# STM32F410C8T3 register map
File version: 1.0
Registers are 32-bit, access not given, reset 0x0 unless marked. A register's access mark holds for its fields unless they carry their own. Offsets are from the block's base; [hi:lo] are bit positions; {n}, {i} and the like mark numbered series.

## WWDG
Base 0x40002C00
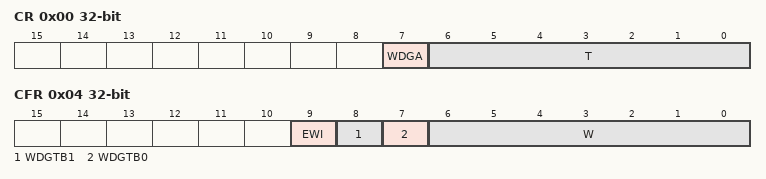
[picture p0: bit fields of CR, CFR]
0x00 CR
  [7] WDGA, [6:0] T
0x04 CFR
  [9] EWI, [8] WDGTB1, [7] WDGTB0, [6:0] W
0x08 SR
  [0] EWIF

## IWDG
Base 0x40003000
0x00 KR
  [15:0] KEY
0x04 PR
  [2:0] PR
0x08 RLR
  [11:0] RL
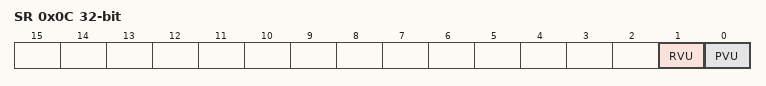
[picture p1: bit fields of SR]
0x0C SR
  [1] RVU, [0] PVU

## SPI2
Base 0x40003800
Same registers: SPI1 0x40013000, SPI5 0x40015000
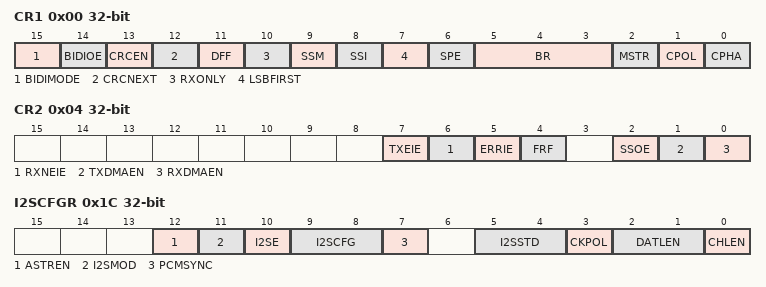
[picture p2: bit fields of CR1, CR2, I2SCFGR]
0x00 CR1
  [15] BIDIMODE, [14] BIDIOE, [13] CRCEN, [12] CRCNEXT, [11] DFF, [10] RXONLY, [9] SSM, [8] SSI, [7] LSBFIRST, [6] SPE, [5:3] BR, [2] MSTR, [1] CPOL, [0] CPHA
0x04 CR2
  [7] TXEIE, [6] RXNEIE, [5] ERRIE, [4] FRF, [2] SSOE, [1] TXDMAEN, [0] RXDMAEN
0x08 SR
0x0C DR
  [15:0] DR
0x10 CRCPR
  [15:0] CRCPOLY
0x14 RXCRCR
  [15:0] RxCRC
0x18 TXCRCR
  [15:0] TxCRC
0x1C I2SCFGR
  [12] ASTREN, [11] I2SMOD, [10] I2SE, [9:8] I2SCFG, [7] PCMSYNC, [5:4] I2SSTD, [3] CKPOL, [2:1] DATLEN, [0] CHLEN
0x20 I2SPR

## USART2
Base 0x40004400
Same registers: USART1 0x40011000, USART6 0x40011400
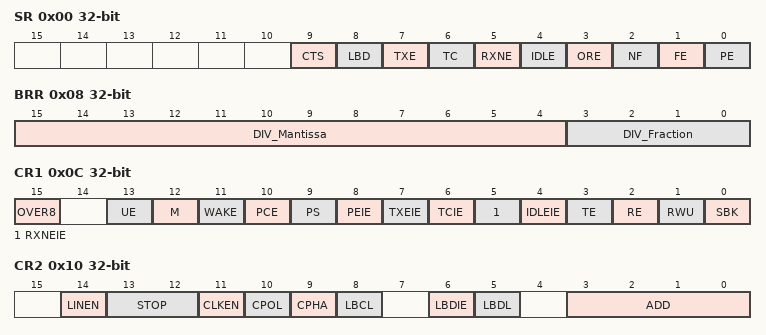
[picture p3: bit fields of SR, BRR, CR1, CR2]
0x00 SR
  [9] CTS, [8] LBD, [7] TXE, [6] TC, [5] RXNE, [4] IDLE, [3] ORE, [2] NF, [1] FE, [0] PE
0x04 DR
  [8:0] DR
0x08 BRR
  [15:4] DIV_Mantissa, [3:0] DIV_Fraction
0x0C CR1
  [15] OVER8, [13] UE, [12] M, [11] WAKE, [10] PCE, [9] PS, [8] PEIE, [7] TXEIE, [6] TCIE, [5] RXNEIE, [4] IDLEIE, [3] TE, [2] RE, [1] RWU, [0] SBK
0x10 CR2
  [14] LINEN, [13:12] STOP, [11] CLKEN, [10] CPOL, [9] CPHA, [8] LBCL, [6] LBDIE, [5] LBDL, [3:0] ADD
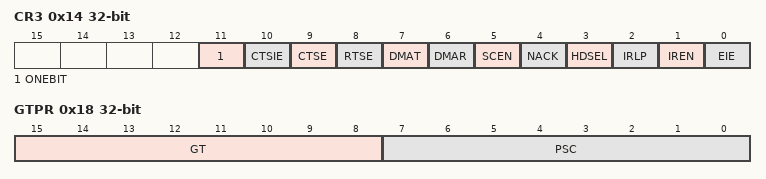
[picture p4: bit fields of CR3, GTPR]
0x14 CR3
  [11] ONEBIT, [10] CTSIE, [9] CTSE, [8] RTSE, [7] DMAT, [6] DMAR, [5] SCEN, [4] NACK, [3] HDSEL, [2] IRLP, [1] IREN, [0] EIE
0x18 GTPR
  [15:8] GT, [7:0] PSC

## I2C1
Base 0x40005400
Same registers: I2C2 0x40005800, I2C4FM 0x40006000
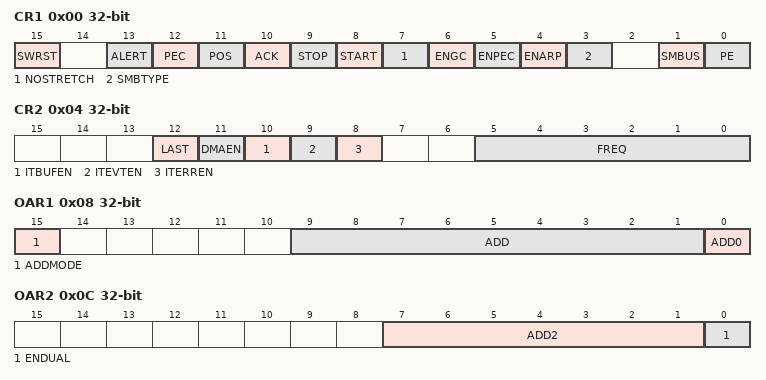
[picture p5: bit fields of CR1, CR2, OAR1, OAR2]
0x00 CR1
  [15] SWRST, [13] ALERT, [12] PEC, [11] POS, [10] ACK, [9] STOP, [8] START, [7] NOSTRETCH, [6] ENGC, [5] ENPEC, [4] ENARP, [3] SMBTYPE, [1] SMBUS, [0] PE
0x04 CR2
  [12] LAST, [11] DMAEN, [10] ITBUFEN, [9] ITEVTEN, [8] ITERREN, [5:0] FREQ
0x08 OAR1
  [15] ADDMODE, [9:1] ADD, [0] ADD0
0x0C OAR2
  [7:1] ADD2, [0] ENDUAL
0x10 DR
  [7:0] DR
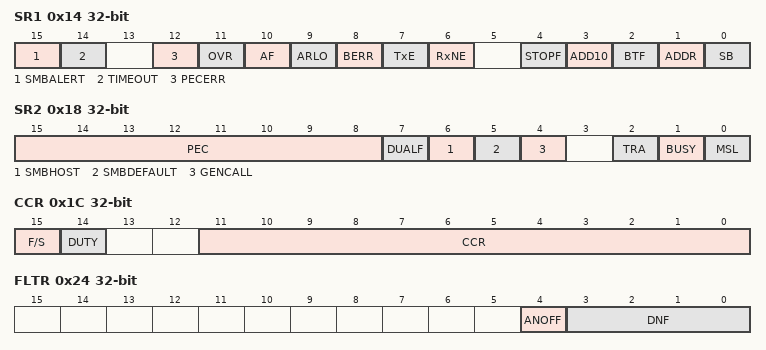
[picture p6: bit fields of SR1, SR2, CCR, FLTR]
0x14 SR1
  [15] SMBALERT, [14] TIMEOUT, [12] PECERR, [11] OVR, [10] AF, [9] ARLO, [8] BERR, [7] TxE, [6] RxNE, [4] STOPF, [3] ADD10, [2] BTF, [1] ADDR, [0] SB
0x18 SR2
  [15:8] PEC, [7] DUALF, [6] SMBHOST, [5] SMBDEFAULT, [4] GENCALL, [2] TRA, [1] BUSY, [0] MSL
0x1C CCR
  [15] F/S, [14] DUTY, [11:0] CCR
0x20 TRISE
  [5:0] TRISE
0x24 FLTR
  [4] ANOFF, [3:0] DNF

## PWR
Base 0x40007000
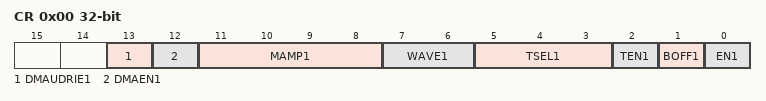
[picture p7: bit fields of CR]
0x00 CR
0x04 CSR

## DAC
Base 0x40007400
0x00 CR
  [13] DMAUDRIE1, [12] DMAEN1, [11:8] MAMP1, [7:6] WAVE1, [5:3] TSEL1, [2] TEN1, [1] BOFF1, [0] EN1
0x04 SWTRIGR
  [0] SWTRIG1
0x08 DHR12R1
  [11:0] DACC1DHR
0x0C DHR12L1
  [15:4] DACC1DHR
0x10 DHR8R1
  [7:0] DACC1DHR
0x2C DOR1
  [11:0] DACC1DOR
0x34 SR
  [13] DMAUDR1

## TIM1
Base 0x40010000
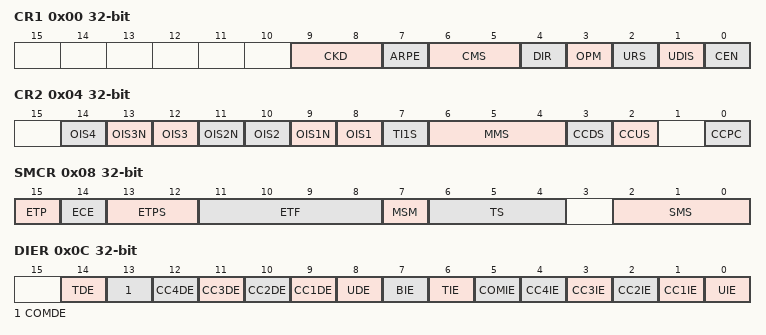
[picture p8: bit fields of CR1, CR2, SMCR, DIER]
0x00 CR1
  [9:8] CKD, [7] ARPE, [6:5] CMS, [4] DIR, [3] OPM, [2] URS, [1] UDIS, [0] CEN
0x04 CR2
  [2n+6] OIS{n} (n=1..4), [13] OIS3N, [11] OIS2N, [9] OIS1N, [7] TI1S, [6:4] MMS, [3] CCDS, [2] CCUS, [0] CCPC
0x08 SMCR
  [15] ETP, [14] ECE, [13:12] ETPS, [11:8] ETF, [7] MSM, [6:4] TS, [2:0] SMS
0x0C DIER
  [14] TDE, [13] COMDE, [n+8] CC{n}DE (n=1..4), [8] UDE, [7] BIE, [6] TIE, [5] COMIE, [n] CC{n}IE (n=1..4), [0] UIE
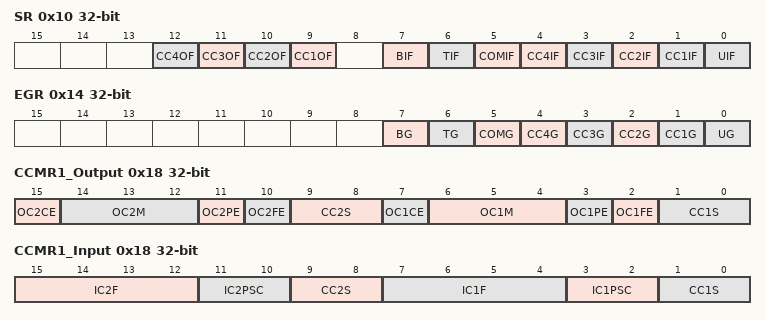
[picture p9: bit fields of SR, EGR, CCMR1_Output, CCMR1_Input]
0x10 SR
  [n+8] CC{n}OF (n=1..4), [7] BIF, [6] TIF, [5] COMIF, [n] CC{n}IF (n=1..4), [0] UIF
0x14 EGR
  [7] BG, [6] TG, [5] COMG, [n] CC{n}G (n=1..4), [0] UG
0x18 CCMR1_Output
  [15] OC2CE, [14:12] OC2M, [11] OC2PE, [10] OC2FE, [9:8] CC2S, [7] OC1CE, [6:4] OC1M, [3] OC1PE, [2] OC1FE, [1:0] CC1S
0x18 CCMR1_Input
  [15:12] IC2F, [11:10] IC2PSC, [9:8] CC2S, [7:4] IC1F, [3:2] IC1PSC, [1:0] CC1S
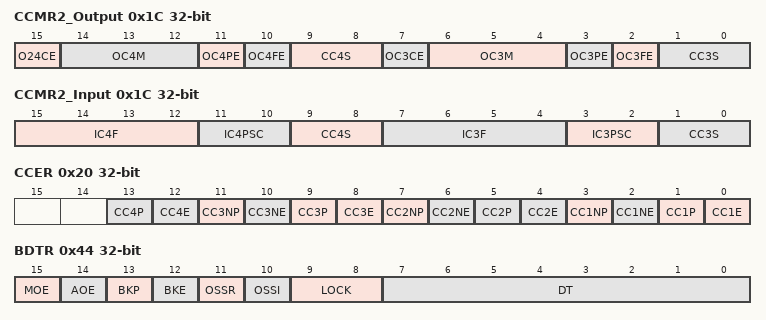
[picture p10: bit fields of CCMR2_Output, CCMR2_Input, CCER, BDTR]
0x1C CCMR2_Output
  [15] O24CE, [14:12] OC4M, [11] OC4PE, [10] OC4FE, [9:8] CC4S, [7] OC3CE, [6:4] OC3M, [3] OC3PE, [2] OC3FE, [1:0] CC3S
0x1C CCMR2_Input
  [15:12] IC4F, [11:10] IC4PSC, [9:8] CC4S, [7:4] IC3F, [3:2] IC3PSC, [1:0] CC3S
0x20 CCER
  [4n-3] CC{n}P (n=1..4), [4n-4] CC{n}E (n=1..4), [11] CC3NP, [10] CC3NE, [7] CC2NP, [6] CC2NE, [3] CC1NP, [2] CC1NE
0x24 CNT
  [15:0] CNT
0x28 PSC
  [15:0] PSC
0x2C ARR
  [15:0] ARR
0x30 RCR
  [7:0] REP
{0x30+4i} CCR{i} (i=1..4)
  [15:0] CCR{i}
0x44 BDTR
  [15] MOE, [14] AOE, [13] BKP, [12] BKE, [11] OSSR, [10] OSSI, [9:8] LOCK, [7:0] DT
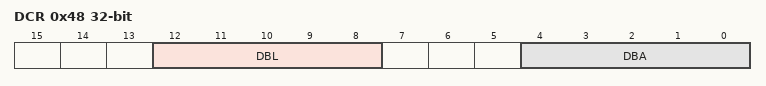
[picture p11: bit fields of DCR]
0x48 DCR
  [12:8] DBL, [4:0] DBA
0x4C DMAR
  [15:0] DMAB
